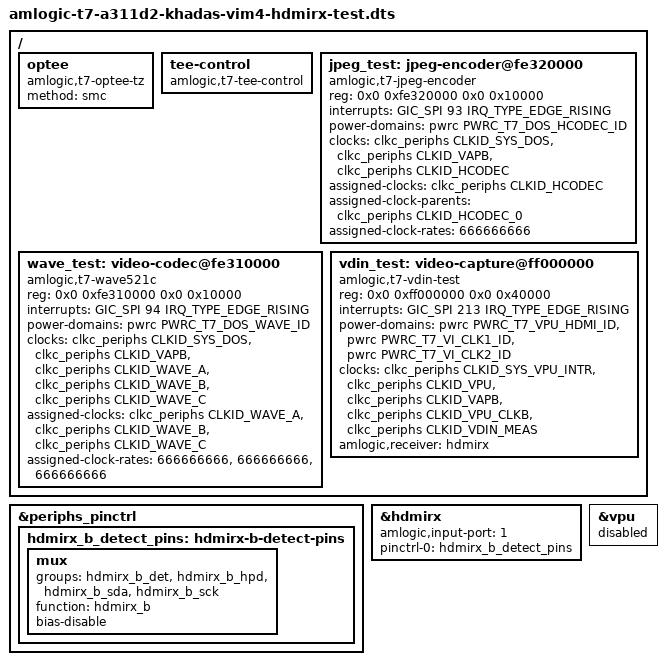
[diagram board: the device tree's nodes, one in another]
// SPDX-License-Identifier: (GPL-2.0+ OR MIT)
/* Receiver resource/cable experiment; the normal VIM4 DTB stays disabled. */
#include "amlogic-t7-a311d2-khadas-vim4-udc-test.dts"

&periphs_pinctrl {
	hdmirx_b_detect_pins: hdmirx-b-detect-pins {
		mux {
			groups = "hdmirx_b_det", "hdmirx_b_hpd",
				 "hdmirx_b_sda", "hdmirx_b_sck";
			function = "hdmirx_b";
			bias-disable;
		};
	};
};

&hdmirx {
	amlogic,input-port = <1>;
	pinctrl-0 = <&hdmirx_b_detect_pins>;
	pinctrl-names = "default";
	status = "okay";
};

/ {
	optee {
		compatible = "amlogic,t7-optee-tz", "linaro,optee-tz";
		method = "smc";
	};
	tee-control {
		compatible = "amlogic,t7-tee-control";
	};

	jpeg_test: jpeg-encoder@fe320000 {
		compatible = "amlogic,t7-jpeg-encoder";
		reg = <0x0 0xfe320000 0x0 0x10000>;
		interrupts = <GIC_SPI 93 IRQ_TYPE_EDGE_RISING>;
		power-domains = <&pwrc PWRC_T7_DOS_HCODEC_ID>;
		clocks = <&clkc_periphs CLKID_SYS_DOS>,
			 <&clkc_periphs CLKID_VAPB>, <&clkc_periphs CLKID_HCODEC>;
		clock-names = "pclk", "apb", "core";
		assigned-clocks = <&clkc_periphs CLKID_HCODEC>;
		/* The secure JPEG loader uses the P0 HCODEC clock path. */
		assigned-clock-parents = <&clkc_periphs CLKID_HCODEC_0>;
		assigned-clock-rates = <666666666>;
	};

	wave_test: video-codec@fe310000 {
		compatible = "amlogic,t7-wave521c";
		reg = <0x0 0xfe310000 0x0 0x10000>;
		interrupts = <GIC_SPI 94 IRQ_TYPE_EDGE_RISING>;
		/* The secure power controller owns the NIC3 AXI bridge reset. */
		power-domains = <&pwrc PWRC_T7_DOS_WAVE_ID>;
		clocks = <&clkc_periphs CLKID_SYS_DOS>,
			 <&clkc_periphs CLKID_VAPB>,
			 <&clkc_periphs CLKID_WAVE_A>,
			 <&clkc_periphs CLKID_WAVE_B>,
			 <&clkc_periphs CLKID_WAVE_C>;
		clock-names = "pclk", "apb", "axi", "bpu", "vce";
		assigned-clocks = <&clkc_periphs CLKID_WAVE_A>,
				  <&clkc_periphs CLKID_WAVE_B>,
				  <&clkc_periphs CLKID_WAVE_C>;
		assigned-clock-rates = <666666666>, <666666666>, <666666666>;
	};

	vdin_test: video-capture@ff000000 {
		compatible = "amlogic,t7-vdin-test";
		reg = <0x0 0xff000000 0x0 0x40000>;
		interrupts = <GIC_SPI 213 IRQ_TYPE_EDGE_RISING>;
		power-domains = <&pwrc PWRC_T7_VPU_HDMI_ID>,
				<&pwrc PWRC_T7_VI_CLK1_ID>, <&pwrc PWRC_T7_VI_CLK2_ID>;
		clocks = <&clkc_periphs CLKID_SYS_VPU_INTR>,
			 <&clkc_periphs CLKID_VPU>, <&clkc_periphs CLKID_VAPB>,
			 <&clkc_periphs CLKID_VPU_CLKB>, <&clkc_periphs CLKID_VDIN_MEAS>;
		clock-names = "pclk", "vpu", "vapb", "clkb", "measure";
		amlogic,receiver = <&hdmirx>;
	};
};

&vpu {
	status = "disabled";
};
